AUTOSAR XML (schema 4-2-2)
package /ComponentTypes
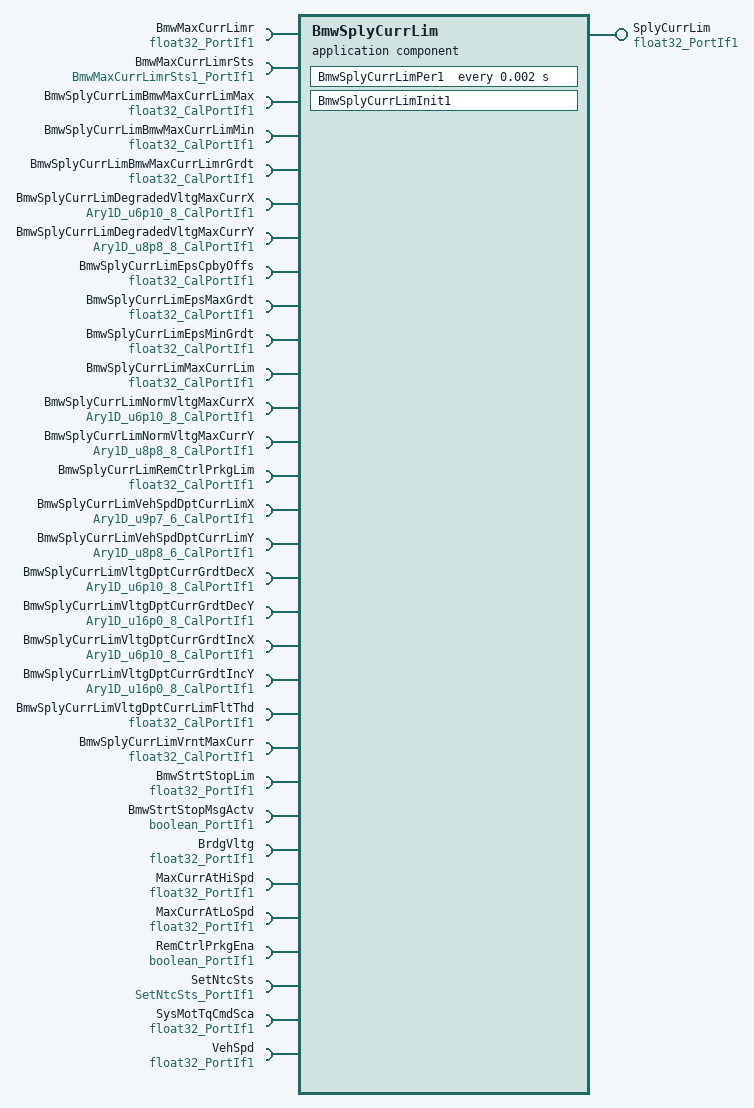
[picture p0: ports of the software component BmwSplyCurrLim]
  application sw component type BmwSplyCurrLim
    provide port SplyCurrLim: nonqueued-sender-com-spec{data-element=Val, init-value=120}, provided-interface=float32_PortIf1
    31 x require port:
      BmwMaxCurrLimr: nonqueued-receiver-com-spec{data-element=Val, filter=data-filter-type=ALWAYS, init-value=120}, required-interface=float32_PortIf1
      BmwMaxCurrLimrSts: nonqueued-receiver-com-spec{data-element=Val, filter=data-filter-type=ALWAYS, init-value=4}, required-interface=BmwMaxCurrLimrSts1_PortIf1
      BmwSplyCurrLimBmwMaxCurrLimMax: parameter-require-com-spec{init-value=120, parameter=Val}, required-interface=float32_CalPortIf1
      BmwSplyCurrLimBmwMaxCurrLimMin: parameter-require-com-spec{init-value=43, parameter=Val}, required-interface=float32_CalPortIf1
      BmwSplyCurrLimBmwMaxCurrLimrGrdt: parameter-require-com-spec{init-value=20, parameter=Val}, required-interface=float32_CalPortIf1
      BmwSplyCurrLimDegradedVltgMaxCurrX: parameter-require-com-spec{init-value=[7168, 10240, 11264, 14336, 17408, 20480, 27648, 32768], parameter=Ary1D}, required-interface=Ary1D_u6p10_8_CalPortIf1
      BmwSplyCurrLimDegradedVltgMaxCurrY: parameter-require-com-spec{init-value=[0, 10880, 10880, 10880, 10880, 10880, 10880, 10880], parameter=Ary1D}, required-interface=Ary1D_u8p8_8_CalPortIf1
      BmwSplyCurrLimEpsCpbyOffs: parameter-require-com-spec{init-value=0, parameter=Val}, required-interface=float32_CalPortIf1
      BmwSplyCurrLimEpsMaxGrdt: parameter-require-com-spec{init-value=50000, parameter=Val}, required-interface=float32_CalPortIf1
      BmwSplyCurrLimEpsMinGrdt: parameter-require-com-spec{init-value=200, parameter=Val}, required-interface=float32_CalPortIf1
      BmwSplyCurrLimMaxCurrLim: parameter-require-com-spec{init-value=120, parameter=Val}, required-interface=float32_CalPortIf1
      BmwSplyCurrLimNormVltgMaxCurrX: parameter-require-com-spec{init-value=[6400, 6912, 7168, 9216, 10240, 11264, 14336, 27648], parameter=Ary1D}, required-interface=Ary1D_u6p10_8_CalPortIf1
      BmwSplyCurrLimNormVltgMaxCurrY: parameter-require-com-spec{init-value=[0, 10880, 10880, 15360, 25600, 30720, 30720, 15360], parameter=Ary1D}, required-interface=Ary1D_u8p8_8_CalPortIf1
      BmwSplyCurrLimRemCtrlPrkgLim: parameter-require-com-spec{init-value=120, parameter=Val}, required-interface=float32_CalPortIf1
      BmwSplyCurrLimVehSpdDptCurrLimX: parameter-require-com-spec{init-value=[0, 640, 1280, 2560, 6400, 12800], parameter=Ary1D}, required-interface=Ary1D_u9p7_6_CalPortIf1
      BmwSplyCurrLimVehSpdDptCurrLimY: parameter-require-com-spec{init-value=[30720, 30720, 26880, 21760, 15360, 15360], parameter=Ary1D}, required-interface=Ary1D_u8p8_6_CalPortIf1
      BmwSplyCurrLimVltgDptCurrGrdtDecX: parameter-require-com-spec{init-value=[10752, 11776, 17920, 18944, 20480, 24576, 27648, 32768], parameter=Ary1D}, required-interface=Ary1D_u6p10_8_CalPortIf1
      BmwSplyCurrLimVltgDptCurrGrdtDecY: parameter-require-com-spec{init-value=[50000, 50000, 50000, 800, 800, 800, 800, 800], parameter=Ary1D}, required-interface=Ary1D_u16p0_8_CalPortIf1
      BmwSplyCurrLimVltgDptCurrGrdtIncX: parameter-require-com-spec{init-value=[10752, 11776, 17920, 18944, 20480, 24576, 27648, 32768], parameter=Ary1D}, required-interface=Ary1D_u6p10_8_CalPortIf1
      BmwSplyCurrLimVltgDptCurrGrdtIncY: parameter-require-com-spec{init-value=[800, 50000, 50000, 50000, 50000, 50000, 50000, 50000], parameter=Ary1D}, required-interface=Ary1D_u16p0_8_CalPortIf1
      BmwSplyCurrLimVltgDptCurrLimFltThd: parameter-require-com-spec{init-value=55, parameter=Val}, required-interface=float32_CalPortIf1
      BmwSplyCurrLimVrntMaxCurr: parameter-require-com-spec{init-value=120, parameter=Val}, required-interface=float32_CalPortIf1
      BmwStrtStopLim: nonqueued-receiver-com-spec{data-element=Val, filter=data-filter-type=ALWAYS, init-value=120}, required-interface=float32_PortIf1
      BmwStrtStopMsgActv: nonqueued-receiver-com-spec{data-element=Logl, filter=data-filter-type=ALWAYS, init-value=0}, required-interface=boolean_PortIf1
      BrdgVltg: nonqueued-receiver-com-spec{data-element=Val, filter=data-filter-type=ALWAYS, init-value=6}, required-interface=float32_PortIf1
      MaxCurrAtHiSpd: nonqueued-receiver-com-spec{data-element=Val, filter=data-filter-type=ALWAYS, init-value=120}, required-interface=float32_PortIf1
      MaxCurrAtLoSpd: nonqueued-receiver-com-spec{data-element=Val, filter=data-filter-type=ALWAYS, init-value=120}, required-interface=float32_PortIf1
      RemCtrlPrkgEna: nonqueued-receiver-com-spec{data-element=Logl, filter=data-filter-type=ALWAYS, init-value=0}, required-interface=boolean_PortIf1
      SetNtcSts: client-com-spec=Oper, required-interface=SetNtcSts_PortIf1
      SysMotTqCmdSca: nonqueued-receiver-com-spec{data-element=Val, filter=data-filter-type=ALWAYS, init-value=1}, required-interface=float32_PortIf1
      VehSpd: nonqueued-receiver-com-spec{data-element=Val, filter=data-filter-type=ALWAYS, init-value=0}, required-interface=float32_PortIf1
    behavior BmwSplyCurrLim_InternalBehavior
      ar-typed-per-instance-memorys:
        10 x data, all with sw-calibration-access=READ-ONLY, type=float32:
          BmwMaxCurrLimGrdt
          dBmwSplyCurrLimBmwMaxCurrLim
          dBmwSplyCurrLimCurrLim
          dBmwSplyCurrLimCurrLimPrel
          dBmwSplyCurrLimGlbLim
          dBmwSplyCurrLimSplyCurrLim
          dBmwSplyCurrLimVehSpdDptCurrLim
          dBmwSplyCurrLimVltgDptCurrLim
          SplyCurrLimGrdt
          VltgDptCurrLimGrdt
      init event BmwSplyCurrLim_InitEvent: start-on-event=BmwSplyCurrLimInit1
      timing event TMT_BmwSplyCurrLimPer1: start-on-event=BmwSplyCurrLimPer1, period=0.002
      port-api-options:
        enable-take-address=false, error-handling=NO-TRANSFORMER-ERROR-HANDLING, indirect-api=false, port=BmwMaxCurrLimr
        enable-take-address=false, error-handling=NO-TRANSFORMER-ERROR-HANDLING, indirect-api=false, port=BmwMaxCurrLimrSts
        enable-take-address=false, error-handling=NO-TRANSFORMER-ERROR-HANDLING, indirect-api=false, port=BmwSplyCurrLimBmwMaxCurrLimMax
        enable-take-address=false, error-handling=NO-TRANSFORMER-ERROR-HANDLING, indirect-api=false, port=BmwSplyCurrLimBmwMaxCurrLimMin
        enable-take-address=false, error-handling=NO-TRANSFORMER-ERROR-HANDLING, indirect-api=false, port=BmwSplyCurrLimBmwMaxCurrLimrGrdt
        enable-take-address=false, error-handling=NO-TRANSFORMER-ERROR-HANDLING, indirect-api=false, port=BmwSplyCurrLimDegradedVltgMaxCurrX
        enable-take-address=false, error-handling=NO-TRANSFORMER-ERROR-HANDLING, indirect-api=false, port=BmwSplyCurrLimDegradedVltgMaxCurrY
        enable-take-address=false, error-handling=NO-TRANSFORMER-ERROR-HANDLING, indirect-api=false, port=BmwSplyCurrLimEpsCpbyOffs
        enable-take-address=false, error-handling=NO-TRANSFORMER-ERROR-HANDLING, indirect-api=false, port=BmwSplyCurrLimEpsMaxGrdt
        enable-take-address=false, error-handling=NO-TRANSFORMER-ERROR-HANDLING, indirect-api=false, port=BmwSplyCurrLimEpsMinGrdt
        enable-take-address=false, error-handling=NO-TRANSFORMER-ERROR-HANDLING, indirect-api=false, port=BmwSplyCurrLimMaxCurrLim
        enable-take-address=false, error-handling=NO-TRANSFORMER-ERROR-HANDLING, indirect-api=false, port=BmwSplyCurrLimNormVltgMaxCurrX
        enable-take-address=false, error-handling=NO-TRANSFORMER-ERROR-HANDLING, indirect-api=false, port=BmwSplyCurrLimNormVltgMaxCurrY
        enable-take-address=false, error-handling=NO-TRANSFORMER-ERROR-HANDLING, indirect-api=false, port=BmwSplyCurrLimRemCtrlPrkgLim
        enable-take-address=false, error-handling=NO-TRANSFORMER-ERROR-HANDLING, indirect-api=false, port=BmwSplyCurrLimVehSpdDptCurrLimX
        enable-take-address=false, error-handling=NO-TRANSFORMER-ERROR-HANDLING, indirect-api=false, port=BmwSplyCurrLimVehSpdDptCurrLimY
        enable-take-address=false, error-handling=NO-TRANSFORMER-ERROR-HANDLING, indirect-api=false, port=BmwSplyCurrLimVltgDptCurrGrdtDecX
        enable-take-address=false, error-handling=NO-TRANSFORMER-ERROR-HANDLING, indirect-api=false, port=BmwSplyCurrLimVltgDptCurrGrdtDecY
        enable-take-address=false, error-handling=NO-TRANSFORMER-ERROR-HANDLING, indirect-api=false, port=BmwSplyCurrLimVltgDptCurrGrdtIncX
        enable-take-address=false, error-handling=NO-TRANSFORMER-ERROR-HANDLING, indirect-api=false, port=BmwSplyCurrLimVltgDptCurrGrdtIncY
        enable-take-address=false, error-handling=NO-TRANSFORMER-ERROR-HANDLING, indirect-api=false, port=BmwSplyCurrLimVltgDptCurrLimFltThd
        enable-take-address=false, error-handling=NO-TRANSFORMER-ERROR-HANDLING, indirect-api=false, port=BmwSplyCurrLimVrntMaxCurr
        enable-take-address=false, error-handling=NO-TRANSFORMER-ERROR-HANDLING, indirect-api=false, port=BmwStrtStopLim
        enable-take-address=false, error-handling=NO-TRANSFORMER-ERROR-HANDLING, indirect-api=false, port=BmwStrtStopMsgActv
        enable-take-address=false, error-handling=NO-TRANSFORMER-ERROR-HANDLING, indirect-api=false, port=BrdgVltg
        enable-take-address=false, error-handling=NO-TRANSFORMER-ERROR-HANDLING, indirect-api=false, port=MaxCurrAtHiSpd
        enable-take-address=false, error-handling=NO-TRANSFORMER-ERROR-HANDLING, indirect-api=false, port=MaxCurrAtLoSpd
        enable-take-address=false, error-handling=NO-TRANSFORMER-ERROR-HANDLING, indirect-api=false, port=RemCtrlPrkgEna
        enable-take-address=false, error-handling=NO-TRANSFORMER-ERROR-HANDLING, indirect-api=false, port=SetNtcSts
        enable-take-address=false, error-handling=NO-TRANSFORMER-ERROR-HANDLING, indirect-api=false, port=SplyCurrLim
        enable-take-address=false, error-handling=NO-TRANSFORMER-ERROR-HANDLING, indirect-api=false, port=SysMotTqCmdSca
        enable-take-address=false, error-handling=NO-TRANSFORMER-ERROR-HANDLING, indirect-api=false, port=VehSpd
      runnable BmwSplyCurrLimInit1
      runnable BmwSplyCurrLimPer1
        data-receive-point-by-arguments:
          10 x access:
            REC_BmwMaxCurrLimr_Val: accessed-variable=BmwMaxCurrLimr.Val
            REC_BmwMaxCurrLimrSts_Val: accessed-variable=BmwMaxCurrLimrSts.Val
            REC_BmwStrtStopLim_Val: accessed-variable=BmwStrtStopLim.Val
            REC_BmwStrtStopMsgActv_Logl: accessed-variable=BmwStrtStopMsgActv.Logl
            REC_BrdgVltg_Val: accessed-variable=BrdgVltg.Val
            REC_MaxCurrAtHiSpd_Val: accessed-variable=MaxCurrAtHiSpd.Val
            REC_MaxCurrAtLoSpd_Val: accessed-variable=MaxCurrAtLoSpd.Val
            REC_RemCtrlPrkgEna_Logl: accessed-variable=RemCtrlPrkgEna.Logl
            REC_SysMotTqCmdSca_Val: accessed-variable=SysMotTqCmdSca.Val
            REC_VehSpd_Val: accessed-variable=VehSpd.Val
        data-send-points:
          access SEND_SplyCurrLim_Val: accessed-variable=SplyCurrLim.Val
        sync call SC_SetNtcSts_Oper: operation=SetNtcSts.Oper, timeout=0
  swc implementation BmwSplyCurrLim_Implementation: behavior=BmwSplyCurrLim_InternalBehavior
    code-descriptors:
      code Default: artifact-descriptors=autosar-engineering-object={short-label=Default, category=SWSRC}
